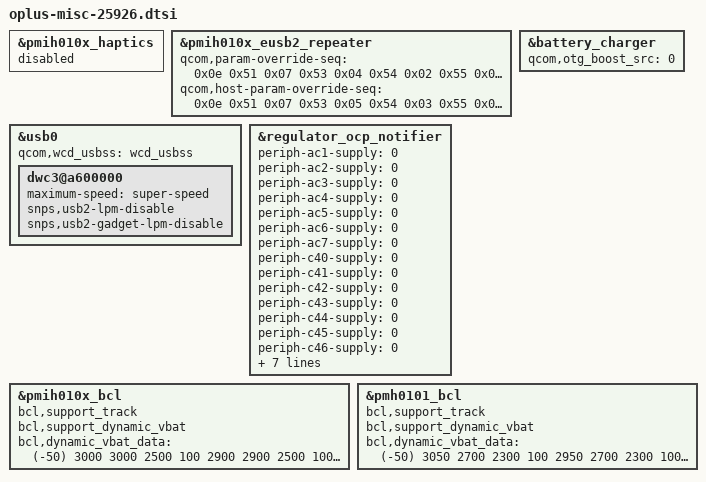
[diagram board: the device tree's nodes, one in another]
&pmih010x_haptics {
	status = "disabled";
};

&pmih010x_eusb2_repeater {
	qcom,param-override-seq = <0x0e 0x51 0x07 0x53 0x04 0x54 0x02 0x55 0x05 0x57>;
	qcom,host-param-override-seq = <0x0e 0x51 0x07 0x53 0x05 0x54 0x03 0x55 0x05 0x57>;
};

&usb0 {
	qcom,wcd_usbss = <&wcd_usbss>;
	dwc3@a600000 {
		maximum-speed = "super-speed";
		snps,usb2-lpm-disable;
		snps,usb2-gadget-lpm-disable;
	};
};

&battery_charger {
	qcom,otg_boost_src = <0>; /* 0:plat_pmic 1:external */
};

&regulator_ocp_notifier {
	periph-ac1-supply = <0>;
	periph-ac2-supply = <0>;
	periph-ac3-supply = <0>;
	periph-ac4-supply = <0>;
	periph-ac5-supply = <0>;
	periph-ac6-supply = <0>;
	periph-ac7-supply = <0>;
	periph-c40-supply = <0>;
	periph-c41-supply = <0>;
	periph-c42-supply = <0>;
	periph-c43-supply = <0>;
	periph-c44-supply = <0>;
	periph-c45-supply = <0>;
	periph-c46-supply = <0>;
	periph-d40-supply = <0>;
	periph-d41-supply = <0>;
	periph-d42-supply = <0>;
	periph-d43-supply = <0>;
	periph-d44-supply = <0>;
	periph-d45-supply = <0>;
	periph-d46-supply = <0>;
};

&pmih010x_bcl {
    bcl,support_track;
    bcl,support_dynamic_vbat;
    bcl,dynamic_vbat_data = <(-50) 3000 3000 2500
                100 2900 2900 2500
                1000 2800 2800 2500>;
};

&pmh0101_bcl {
    bcl,support_track;
    bcl,support_dynamic_vbat;
    bcl,dynamic_vbat_data = <(-50) 3050 2700 2300
                100 2950 2700 2300
                1000 2850 2700 2300>;
};
